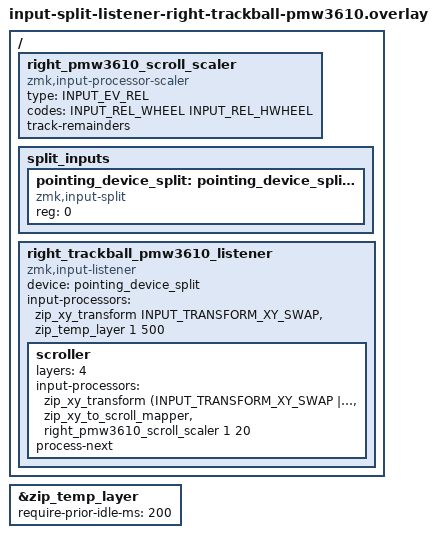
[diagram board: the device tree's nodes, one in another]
#include <dt-bindings/zmk/input_transform.h>
#include <input/processors.dtsi>

&zip_temp_layer {
    require-prior-idle-ms = <200>;
};

/ {
    right_pmw3610_scroll_scaler: right_pmw3610_scroll_scaler {
        compatible = "zmk,input-processor-scaler";
        #input-processor-cells = <2>;
        type = <INPUT_EV_REL>;
        codes = <INPUT_REL_WHEEL INPUT_REL_HWHEEL>;
        track-remainders;
    };

    split_inputs {
        #address-cells = <1>;
        #size-cells = <0>;

        pointing_device_split: pointing_device_split@0 {
            compatible = "zmk,input-split";
            reg = <0>;
        };
    };

    right_trackball_pmw3610_listener: right_trackball_pmw3610_listener {
        compatible = "zmk,input-listener";
        device = <&pointing_device_split>;
        input-processors =
            <&zip_xy_transform INPUT_TRANSFORM_XY_SWAP>,
            <&zip_temp_layer 1 500>;

        scroller {
            layers = <4>;
            input-processors =
                <&zip_xy_transform (INPUT_TRANSFORM_XY_SWAP | INPUT_TRANSFORM_Y_INVERT)>,
                <&zip_xy_to_scroll_mapper>,
                <&right_pmw3610_scroll_scaler 1 20>;
            process-next;
        };
    };
};
